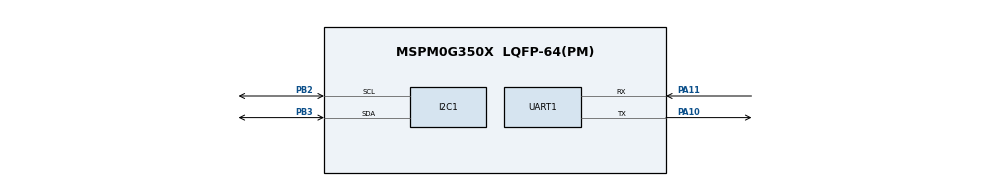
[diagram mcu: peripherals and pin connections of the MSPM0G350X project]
/**
 * @cliArgs --device "MSPM0G350X" --part "Default" --package "LQFP-64(PM)" --product "mspm0_sdk@2.04.00.06"
 * @versions {"tool":"1.21.1+3772"}
 */

/**
 * Import the modules used in this configuration.
 */
const GPIO    = scripting.addModule("/ti/driverlib/GPIO", {}, false);
const GPIO1   = GPIO.addInstance();
const GPIO2   = GPIO.addInstance();
const I2C     = scripting.addModule("/ti/driverlib/I2C", {}, false);
const I2C1    = I2C.addInstance();
const SYSCTL  = scripting.addModule("/ti/driverlib/SYSCTL");
const SYSTICK = scripting.addModule("/ti/driverlib/SYSTICK");
const UART    = scripting.addModule("/ti/driverlib/UART", {}, false);
const UART1   = UART.addInstance();

/**
 * Write custom configuration values to the imported modules.
 */
const divider5       = system.clockTree["PLL_CLK1_DIV"];
divider5.divideValue = 4;

const divider6       = system.clockTree["PLL_CLK2X_DIV"];
divider6.divideValue = 4;

const divider7       = system.clockTree["PLL_PDIV"];
divider7.divideValue = 2;

const divider9       = system.clockTree["UDIV"];
divider9.divideValue = 2;

const gate7  = system.clockTree["MFCLKGATE"];
gate7.enable = true;

const gate8  = system.clockTree["MFPCLKGATE"];
gate8.enable = true;

const multiplier2         = system.clockTree["PLL_QDIV"];
multiplier2.multiplyValue = 10;

const mux4       = system.clockTree["EXHFMUX"];
mux4.inputSelect = "EXHFMUX_XTAL";

const mux8       = system.clockTree["HSCLKMUX"];
mux8.inputSelect = "HSCLKMUX_SYSPLL2X";

GPIO1.$name                          = "LED";
GPIO1.associatedPins[0].$name        = "UserLED";
GPIO1.associatedPins[0].assignedPort = "PORTB";
GPIO1.associatedPins[0].assignedPin  = "9";

const Board = scripting.addModule("/ti/driverlib/Board", {}, false);

GPIO2.$name                              = "MPU6050";
GPIO2.associatedPins[0].$name            = "INT_PIN";
GPIO2.associatedPins[0].direction        = "INPUT";
GPIO2.associatedPins[0].internalResistor = "PULL_UP";
GPIO2.associatedPins[0].interruptEn      = true;
GPIO2.associatedPins[0].polarity         = "FALL";
GPIO2.associatedPins[0].assignedPort     = "PORTB";
GPIO2.associatedPins[0].assignedPin      = "0";

I2C1.$name                           = "I2C_0";
I2C1.basicEnableController           = true;
I2C1.basicControllerStandardBusSpeed = "Fast";
I2C1.peripheral.sdaPin.$assign       = "PB3";
I2C1.peripheral.sclPin.$assign       = "PB2";
I2C1.sdaPinConfig.$name              = "ti_driverlib_gpio_GPIOPinGeneric2";
I2C1.sclPinConfig.$name              = "ti_driverlib_gpio_GPIOPinGeneric3";

SYSCTL.forceDefaultClkConfig = true;
SYSCTL.clockTreeEn           = true;

SYSTICK.systickEnable = true;
SYSTICK.periodEnable  = true;
SYSTICK.period        = 16777215;

UART1.$name                    = "UART_0";
UART1.targetBaudRate           = 115200;
UART1.enabledInterrupts        = ["RX"];
UART1.peripheral.rxPin.$assign = "PA11";
UART1.peripheral.txPin.$assign = "PA10";
UART1.txPinConfig.$name        = "ti_driverlib_gpio_GPIOPinGeneric0";
UART1.rxPinConfig.$name        = "ti_driverlib_gpio_GPIOPinGeneric1";

/**
 * Pinmux solution for unlocked pins/peripherals. This ensures that minor changes to the automatic solver in a future
 * version of the tool will not impact the pinmux you originally saw.  These lines can be completely deleted in order to
 * re-solve from scratch.
 */
GPIO1.associatedPins[0].pin.$suggestSolution = "PB9";
Board.peripheral.$suggestSolution            = "DEBUGSS";
Board.peripheral.swclkPin.$suggestSolution   = "PA20";
Board.peripheral.swdioPin.$suggestSolution   = "PA19";
GPIO2.associatedPins[0].pin.$suggestSolution = "PB0";
I2C1.peripheral.$suggestSolution             = "I2C1";
UART1.peripheral.$suggestSolution            = "UART0";
